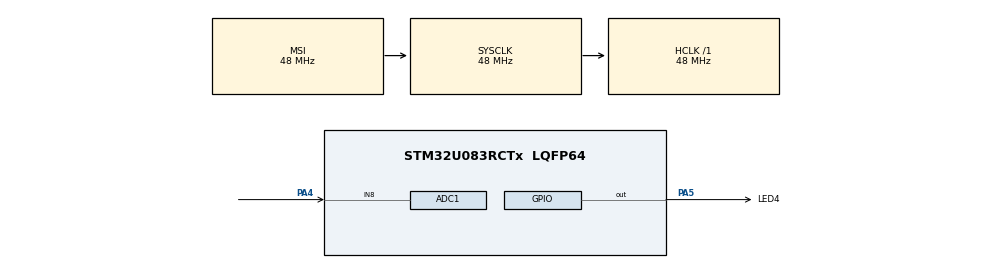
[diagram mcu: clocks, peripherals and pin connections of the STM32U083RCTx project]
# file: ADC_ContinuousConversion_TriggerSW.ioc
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ADC1.Channel-1\#ChannelRegularConversion=ADC_CHANNEL_8
ADC1.ClockPrescaler=ADC_CLOCK_SYNC_PCLK_DIV4
ADC1.ContinuousConvMode=ENABLE
ADC1.NbrOfConversionFlag=1
ADC1.Overrun=ADC_OVR_DATA_OVERWRITTEN
ADC1.Rank-1\#ChannelRegularConversion=1
ADC1.RankArg-1\#ChannelRegularConversion=ADC_REGULAR_RANK_1
ADC1.SamplingTime-1\#ChannelRegularConversion=ADC_SAMPLINGTIME_COMMON_1
ADC1.SamplingTimeCommon1=ADC_SAMPLETIME_79CYCLES_5
ADC1.SelectedChannel=ADC_CHANNEL_8
ADC1.master=1
Mcu.Family=STM32U0
Mcu.Name=STM32U083RCTx
Mcu.Package=LQFP64
NVIC.PriorityGroup=NVIC_PRIORITYGROUP_2
PA4.Mode=IN8
PA4.Signal=ADC1_IN8
PA5.GPIO_Label=LED4
PA5.Signal=GPIO_Output
ProjectManager.HeapSize=0x200
ProjectManager.StackSize=0x400
ProjectManager.TargetToolchain=EWARM V9.20
RCC.ADCFreq_Value=48000000
RCC.AHBFreq_Value=48000000
RCC.CortexFreq_Value=48000000
RCC.HCLKFreq_Value=48000000
RCC.HSE_VALUE=4000000
RCC.HSI48_VALUE=48000000
RCC.HSI_VALUE=16000000
RCC.LSE_VALUE=32768
RCC.MSIClockRangeVal=RCC_MSIRANGE_11
RCC.MSI_VALUE=48000000
RCC.SYSCLKFreq_VALUE=48000000
RCC.SYSCLKSource=RCC_SYSCLKSOURCE_MSI
RCC.USBFreq_Value=48000000
RCC.VCOOutputFreq_Value=64000000
VP_PWR_VS_SECSignals.Mode=Security/Privilege
board=custom

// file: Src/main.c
/* USER CODE BEGIN Header */
/**
  ******************************************************************************
  * @file    Examples/ADC/ADC_ContinuousConversion_TriggerSW/Src/main.c
  * @author  MCD Application Team
  * @brief   Use ADC to convert a single channel continuously,
  *          from a software start.
  *          This example is based on the STM32U0xx ADC HAL API.
  ******************************************************************************
  * @attention
  *
  * Copyright (c) 2023 STMicroelectronics.
  * All rights reserved.
  *
  * This software is licensed under terms that can be found in the LICENSE file
  * in the root directory of this software component.
  * If no LICENSE file comes with this software, it is provided AS-IS.
  ******************************************************************************
  */
/* USER CODE END Header */
#include "main.h"

/* USER CODE BEGIN PD */

/* Definitions of environment analog values */
  /* Value of analog reference voltage (Vref+), connected to analog voltage   */
  /* supply Vdda (unit: mV).                                                  */
  #define VDDA_APPLI                       (3300UL)

/* Definitions of data related to this example */
  /* Init variable out of expected ADC conversion data range */
  #define VAR_CONVERTED_DATA_INIT_VALUE    (__LL_ADC_DIGITAL_SCALE(LL_ADC_RESOLUTION_12B) + 1)

/* USER CODE END PD */

ADC_HandleTypeDef hadc1;

/* USER CODE BEGIN PV */

/* Variables for ADC conversion data */
__IO uint16_t uhADCxConvertedData = VAR_CONVERTED_DATA_INIT_VALUE; /* ADC group regular conversion data */

/* Variables for ADC conversion data computation to physical values */
uint16_t uhADCxConvertedData_Voltage_mVolt = 0;  /* Value of voltage calculated from ADC conversion data (unit: mV) */

/* USER CODE END PV */

void SystemClock_Config(void);
static void MX_GPIO_Init(void);
static void MX_ADC1_Init(void);

int main(void)
{

  /* MCU Configuration--------------------------------------------------------*/

  /* Reset of all peripherals, Initializes the Flash interface and the Systick. */
  HAL_Init();

  /* Configure the system clock */
  SystemClock_Config();

  /* Initialize all configured peripherals */
  MX_GPIO_Init();
  MX_ADC1_Init();
  /* USER CODE BEGIN 2 */

  /* Initialize LED on board */
  BSP_LED_Init(LED4);

  /* Perform ADC calibration */
  if (HAL_ADCEx_Calibration_Start(&hadc1) != HAL_OK)
  {
    /* Calibration Error */
    Error_Handler();
  }

    /* Start ADC group regular conversion */
    if (HAL_ADC_Start(&hadc1) != HAL_OK)
    {
      /* ADC conversion start error */
      Error_Handler();
    }

    /* Wait for ADC conversion completed */
    if (HAL_ADC_PollForConversion(&hadc1, 10) != HAL_OK)
    {
      /* End Of Conversion flag not set on time */
      Error_Handler();
    }

  /* USER CODE END 2 */

  /* Infinite loop */
  /* USER CODE BEGIN WHILE */
  while (1)
  {
    /* Retrieve ADC conversion data */
    uhADCxConvertedData = HAL_ADC_GetValue(&hadc1);

    /* Computation of ADC conversions raw data to physical values             */
    /* using helper macro.                                                    */
    uhADCxConvertedData_Voltage_mVolt = __LL_ADC_CALC_DATA_TO_VOLTAGE(VDDA_APPLI, uhADCxConvertedData, LL_ADC_RESOLUTION_12B);

    /* Toggle LED at each ADC conversion data retrieved */
    BSP_LED_On(LED4);
    HAL_Delay(LED_BLINK_SLOW);
    BSP_LED_Off(LED4);
    HAL_Delay(LED_BLINK_SLOW);

    /* For this example purpose, check that conversion data has been updated
       using flag ADC group regular end of unitary conversion */
    if(__HAL_ADC_GET_FLAG(&hadc1, ADC_FLAG_EOC) == 0)
    {
      Error_Handler();
    }
    __HAL_ADC_CLEAR_FLAG(&hadc1, ADC_FLAG_EOC);

    /* Note: ADC group regular conversions data are stored into array         */
    /*       "uhADCxConvertedData"                                            */
    /*       (for debug: see variable content into watch window).             */

    /* Note: ADC conversion data are computed to physical values              */
    /*       into array "uhADCxConvertedData_Voltage_mVolt" using             */
    /*       ADC LL driver helper macro "__LL_ADC_CALC_DATA_TO_VOLTAGE()"     */
    /*       (for debug: see variable content with debugger)                  */

    /* USER CODE END WHILE */

  }
}

void SystemClock_Config(void)
{
  RCC_OscInitTypeDef RCC_OscInitStruct = {0};
  RCC_ClkInitTypeDef RCC_ClkInitStruct = {0};

  /** Configure the main internal regulator output voltage
  */
  HAL_PWREx_ControlVoltageScaling(PWR_REGULATOR_VOLTAGE_SCALE1);

  /** Initializes the RCC Oscillators according to the specified parameters
  * in the RCC_OscInitTypeDef structure.
  */
  RCC_OscInitStruct.OscillatorType = RCC_OSCILLATORTYPE_MSI;
  RCC_OscInitStruct.MSIState = RCC_MSI_ON;
  RCC_OscInitStruct.MSICalibrationValue = RCC_MSICALIBRATION_DEFAULT;
  RCC_OscInitStruct.MSIClockRange = RCC_MSIRANGE_11;
  RCC_OscInitStruct.PLL.PLLState = RCC_PLL_NONE;
  if (HAL_RCC_OscConfig(&RCC_OscInitStruct) != HAL_OK)
  {
    Error_Handler();
  }

  /** Initializes the CPU, AHB and APB buses clocks
  */
  RCC_ClkInitStruct.ClockType = RCC_CLOCKTYPE_HCLK|RCC_CLOCKTYPE_SYSCLK
                              |RCC_CLOCKTYPE_PCLK1;
  RCC_ClkInitStruct.SYSCLKSource = RCC_SYSCLKSOURCE_MSI;
  RCC_ClkInitStruct.AHBCLKDivider = RCC_SYSCLK_DIV1;
  RCC_ClkInitStruct.APB1CLKDivider = RCC_HCLK_DIV1;

  if (HAL_RCC_ClockConfig(&RCC_ClkInitStruct, FLASH_LATENCY_1) != HAL_OK)
  {
    Error_Handler();
  }
}

static void MX_ADC1_Init(void)
{

  ADC_ChannelConfTypeDef sConfig = {0};

  /** Configure the global features of the ADC (Clock, Resolution, Data Alignment and number of conversion)
  */
  hadc1.Instance = ADC1;
  hadc1.Init.ClockPrescaler = ADC_CLOCK_SYNC_PCLK_DIV4;
  hadc1.Init.Resolution = ADC_RESOLUTION_12B;
  hadc1.Init.DataAlign = ADC_DATAALIGN_RIGHT;
  hadc1.Init.ScanConvMode = ADC_SCAN_DISABLE;
  hadc1.Init.EOCSelection = ADC_EOC_SINGLE_CONV;
  hadc1.Init.LowPowerAutoWait = DISABLE;
  hadc1.Init.LowPowerAutoPowerOff = DISABLE;
  hadc1.Init.ContinuousConvMode = ENABLE;
  hadc1.Init.NbrOfConversion = 1;
  hadc1.Init.ExternalTrigConv = ADC_SOFTWARE_START;
  hadc1.Init.ExternalTrigConvEdge = ADC_EXTERNALTRIGCONVEDGE_NONE;
  hadc1.Init.DMAContinuousRequests = DISABLE;
  hadc1.Init.Overrun = ADC_OVR_DATA_OVERWRITTEN;
  hadc1.Init.SamplingTimeCommon1 = ADC_SAMPLETIME_79CYCLES_5;
  hadc1.Init.SamplingTimeCommon2 = ADC_SAMPLETIME_1CYCLE_5;
  hadc1.Init.OversamplingMode = DISABLE;
  hadc1.Init.TriggerFrequencyMode = ADC_TRIGGER_FREQ_HIGH;
  if (HAL_ADC_Init(&hadc1) != HAL_OK)
  {
    Error_Handler();
  }

  /** Configure Regular Channel
  */
  sConfig.Channel = ADC_CHANNEL_8;
  sConfig.Rank = ADC_REGULAR_RANK_1;
  sConfig.SamplingTime = ADC_SAMPLINGTIME_COMMON_1;
  if (HAL_ADC_ConfigChannel(&hadc1, &sConfig) != HAL_OK)
  {
    Error_Handler();
  }

}

static void MX_GPIO_Init(void)
{
  GPIO_InitTypeDef GPIO_InitStruct = {0};

  /* GPIO Ports Clock Enable */
  __HAL_RCC_GPIOA_CLK_ENABLE();

  /*Configure GPIO pin Output Level */
  HAL_GPIO_WritePin(LED4_GPIO_Port, LED4_Pin, GPIO_PIN_RESET);

  /*Configure GPIO pin : LED4_Pin */
  GPIO_InitStruct.Pin = LED4_Pin;
  GPIO_InitStruct.Mode = GPIO_MODE_OUTPUT_PP;
  GPIO_InitStruct.Pull = GPIO_NOPULL;
  GPIO_InitStruct.Speed = GPIO_SPEED_FREQ_LOW;
  HAL_GPIO_Init(LED4_GPIO_Port, &GPIO_InitStruct);

}

void Error_Handler(void)
{
  /* USER CODE BEGIN Error_Handler_Debug */
  /* User can add his own implementation to report the HAL error return state */

  /* Turn on LED and remain in infinite loop */
  while (1)
  {
    BSP_LED_On(LED4);
  }
  /* USER CODE END Error_Handler_Debug */
}
